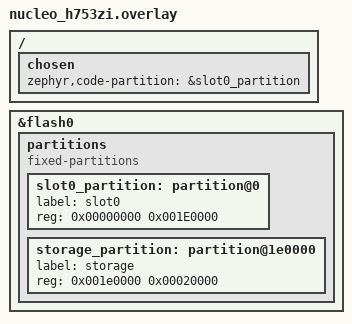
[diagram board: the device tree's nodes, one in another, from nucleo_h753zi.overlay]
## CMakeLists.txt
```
# SPDX-License-Identifier: Apache-2.0

cmake_minimum_required(VERSION 3.20.0)

find_package(Zephyr REQUIRED HINTS $ENV{ZEPHYR_BASE})
find_package(Python REQUIRED COMPONENTS Interpreter)

project(http_server)

if(CONFIG_NET_SOCKETS_SOCKOPT_TLS AND
   CONFIG_MBEDTLS_KEY_EXCHANGE_PSK_ENABLED AND
   (CONFIG_NET_SAMPLE_PSK_HEADER_FILE STREQUAL "dummy_psk.h"))
  add_custom_target(development_psk
    COMMAND ${CMAKE_COMMAND} -E echo "----------------------------------------------------------"
    COMMAND ${CMAKE_COMMAND} -E echo "--- WARNING: Using dummy PSK! Only suitable for        ---"
    COMMAND ${CMAKE_COMMAND} -E echo "--- development. Set NET_SAMPLE_PSK_HEADER_FILE to use ---"
    COMMAND ${CMAKE_COMMAND} -E echo "--- own pre-shared key.                                ---"
    COMMAND ${CMAKE_COMMAND} -E echo "----------------------------------------------------------"
  )
  add_dependencies(app development_psk)
endif()

set(CERTS_DIR ${CMAKE_CURRENT_SOURCE_DIR}/src/certs)

add_custom_target(sample_ca_cert
  WORKING_DIRECTORY ${CERTS_DIR}
  COMMAND sh gen_ca_cert.sh
  COMMENT "Generating sample CA certificate"
)

add_custom_target(sample_server_cert
  WORKING_DIRECTORY ${CERTS_DIR}
  COMMAND sh gen_server_cert.sh
  COMMENT "Generating sample server certificate"
)

option(INCLUDE_HTML_CONTENT "Include the HTML content" ON)

target_sources(app PRIVATE src/main.c
        src/InductionConfig.c
        src/DHCPClient.c
        src/HTTPWebsocket.c
        src/Flash.c
        #src/vlan.c
        #src/HTTPServer.c
)

set(gen_dir ${ZEPHYR_BINARY_DIR}/include/generated/)

target_sources_ifdef(CONFIG_NET_SAMPLE_WEBSOCKET_SERVICE app PRIVATE src/ws.c)
target_sources_ifdef(CONFIG_USB_DEVICE_STACK app PRIVATE src/usb.c)

target_link_libraries(app PRIVATE zephyr_interface zephyr)

zephyr_linker_sources(SECTIONS sections-rom.ld)
zephyr_linker_section_ifdef(CONFIG_NET_SAMPLE_HTTPS_SERVICE NAME
				http_resource_desc_test_https_service
				KVMA RAM_REGION GROUP RODATA_REGION
				SUBALIGN ${CONFIG_LINKER_ITERABLE_SUBALIGN})
zephyr_linker_section_ifdef(CONFIG_NET_SAMPLE_HTTP_SERVICE NAME
				http_resource_desc_test_http_service
				KVMA RAM_REGION GROUP RODATA_REGION
				SUBALIGN ${CONFIG_LINKER_ITERABLE_SUBALIGN})

foreach(web_resource
  index.html
  main.js
    )
  generate_inc_file_for_target(
    app
    src/static_web_resources/${web_resource}
    ${gen_dir}/${web_resource}.gz.inc
    --gzip
  )
endforeach()

foreach(inc_file
	server_cert.der
	server_privkey.der
    )
  generate_inc_file_for_target(
    app
    src/certs/${inc_file}
    ${gen_dir}/${inc_file}.inc
    )
endforeach()
```

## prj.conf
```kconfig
# General config
CONFIG_MAIN_STACK_SIZE=3072
CONFIG_SYSTEM_WORKQUEUE_STACK_SIZE=2048
CONFIG_SHELL=y
CONFIG_LOG=y
CONFIG_ENTROPY_GENERATOR=y
CONFIG_TEST_RANDOM_GENERATOR=y
CONFIG_INIT_STACKS=y
CONFIG_ZVFS_OPEN_MAX=32
CONFIG_POSIX_API=y
CONFIG_FDTABLE=y
CONFIG_ZVFS_POLL_MAX=32

# Eventfd
CONFIG_EVENTFD=y

# Networking config
CONFIG_NETWORKING=y
CONFIG_NET_IPV4=y
CONFIG_NET_IPV6=y
CONFIG_NET_TCP=y
CONFIG_NET_SOCKETS=y
CONFIG_NET_CONNECTION_MANAGER=y
CONFIG_NET_SHELL=y
CONFIG_NET_STATISTICS=y
CONFIG_NET_STATISTICS_USER_API=y
CONFIG_NET_LOG=y

# DHCP client support
CONFIG_NET_DHCPV4=y
CONFIG_NET_MGMT=y
CONFIG_NET_MGMT_EVENT=y
CONFIG_NET_MGMT_EVENT_INFO=y
CONFIG_NET_UDP=y
CONFIG_NET_DHCPV4_OPTION_CALLBACKS=y


# JSON
CONFIG_JSON_LIBRARY=y

# HTTP parser
CONFIG_HTTP_PARSER_URL=y
CONFIG_HTTP_PARSER=y
CONFIG_HTTP_SERVER=y
CONFIG_HTTP_SERVER_WEBSOCKET=y

# Network buffers
CONFIG_NET_PKT_RX_COUNT=16
CONFIG_NET_PKT_TX_COUNT=16
CONFIG_NET_BUF_RX_COUNT=128
CONFIG_NET_BUF_TX_COUNT=128
CONFIG_NET_CONTEXT_NET_PKT_POOL=y

# IP address options
CONFIG_NET_IF_UNICAST_IPV6_ADDR_COUNT=3
CONFIG_NET_IF_MCAST_IPV6_ADDR_COUNT=4
CONFIG_NET_MAX_CONTEXTS=32
CONFIG_NET_MAX_CONN=32

# Network address config
CONFIG_NET_CONFIG_SETTINGS=y
CONFIG_NET_CONFIG_NEED_IPV4=y
CONFIG_NET_CONFIG_NEED_IPV6=y
#CONFIG_NET_CONFIG_MY_IPV4_ADDR="192.0.2.1"
#CONFIG_NET_CONFIG_PEER_IPV4_ADDR="192.0.2.2"
#CONFIG_NET_CONFIG_MY_IPV4_GW="192.0.2.2"
#CONFIG_NET_CONFIG_MY_IPV6_ADDR="2001:db8::1"
#CONFIG_NET_CONFIG_PEER_IPV6_ADDR="2001:db8::2"

# Networking tweaks
# Required to handle large number of consecutive connections,
# e.g. when testing with ApacheBench.
CONFIG_NET_TCP_TIME_WAIT_DELAY=0

# Device drivers
CONFIG_GPIO=y
CONFIG_LED=y

# Network debug config
CONFIG_NET_SOCKETS_LOG_LEVEL_DBG=n
CONFIG_NET_HTTP_LOG_LEVEL_DBG=n
CONFIG_NET_IPV6_LOG_LEVEL_DBG=n
CONFIG_NET_IPV6_ND_LOG_LEVEL_DBG=n

#mDNS Setup
CONFIG_MDNS_RESPONDER=y
CONFIG_MDNS_RESOLVER=y        # if you want resolving on the device too
CONFIG_NET_HOSTNAME_ENABLE=y
CONFIG_NET_HOSTNAME="zephyr"

# POSIX / eventfd support
CONFIG_EVENTFD=y
CONFIG_ZVFS_EVENTFD_MAX=4
CONFIG_ZVFS_OPEN_MAX=32
CONFIG_HEAP_MEM_POOL_SIZE=16384

CONFIG_NET_SAMPLE_WEBSOCKET_SERVICE=y

# Flash Config
CONFIG_SETTINGS=y
CONFIG_SETTINGS_NVS=y
CONFIG_NVS=y
CONFIG_NVS_LOG_LEVEL_INF=y  # optional, for debugging
```

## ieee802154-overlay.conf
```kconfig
CONFIG_NET_L2_IEEE802154=y
CONFIG_NET_L2_IEEE802154_SHELL=y
CONFIG_NET_L2_IEEE802154_LOG_LEVEL_INF=y

# 2.4G by default, SubG bands require additional driver support,
# see *-enable-subg.overlay
# Uncomment for 868 MHz
#CONFIG_NET_CONFIG_IEEE802154_CHANNEL=0
# Uncomment for 906 MHz:
#CONFIG_NET_CONFIG_IEEE802154_CHANNEL=1

CONFIG_NET_MGMT_EVENT_STACK_SIZE=2048
CONFIG_NET_L2_IEEE802154_FRAGMENT_REASS_CACHE_SIZE=3

#Debugging
CONFIG_NET_L2_IEEE802154_LOG_LEVEL_DBG=n
CONFIG_NET_SAMPLE_HTTP_SERVER_SERVICE_PORT=100
```

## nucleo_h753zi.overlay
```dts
/ {
	/* Make sure code-partition still points to your app partition */
	chosen {
		zephyr,code-partition = &slot0_partition;
	};
};

/* Internal flash controller */
&flash0 {
	/* Add or extend partitions node */
	partitions {
		compatible = "fixed-partitions";
		#address-cells = <1>;
		#size-cells = <1>;

		/* This is usually already there; keep whatever your board uses */
		slot0_partition: partition@0 {
			label = "slot0";
			reg = <0x00000000 0x001E0000>; /* example: 1.875 MB for app */
		};

		/* New NVS / settings area at the end of flash */
		storage_partition: partition@1e0000 {
			label = "storage";
			reg = <0x001e0000 0x00020000>; /* 128 KB (one sector) */
		};
	};
};
```

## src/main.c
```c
/*
 * Copyright (c) 2023, Emna Rekik
 * Copyright (c) 2024, Nordic Semiconductor
 *
 * SPDX-License-Identifier: Apache-2.0
 */

#include <stdio.h>
#include <zephyr/kernel.h>
#include <zephyr/logging/log.h>

#include "HTTPWebsocket.h"

LOG_MODULE_REGISTER(main, LOG_LEVEL_DBG);

int main(void)
{
    LOG_INF("Starting HTTP WebSocket Server Application");

    // Initialize the HTTP WebSocket server
    httpwebsocket_init();

    // Start the HTTP server
    int ret = httpwebsocket_start();
    if (ret < 0) {
        LOG_ERR("Failed to start HTTP WebSocket server: %d", ret);
        return ret;
    }

    LOG_INF("HTTP WebSocket Server started successfully");

    return 0;
}
```

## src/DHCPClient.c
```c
/* Networking DHCPv4 client */

/*
 * Copyright (c) 2017 ARM Ltd.
 * Copyright (c) 2016 Intel Corporation.
 *
 * SPDX-License-Identifier: Apache-2.0
 */

#include <zephyr/logging/log.h>
LOG_MODULE_REGISTER(net_dhcpv4_client_sample, LOG_LEVEL_DBG);

#include <zephyr/kernel.h>
#include <zephyr/linker/sections.h>
#include <errno.h>
#include <stdio.h>
#include <stdint.h>

#include <zephyr/net/net_if.h>
#include <zephyr/net/net_core.h>
#include <zephyr/net/net_context.h>
#include <zephyr/net/net_mgmt.h>
#include <zephyr/net/dhcpv4.h>

#include "DHCPClient.h"

typedef struct {
    tcp_info_t tcpInfo;
    bool isValide;
} tcp_info_dhcp_t;

tcp_info_dhcp_t TCPInfoDHCP = {
    .isValide = false
};

#define DHCP_OPTION_NTP (42)

static uint8_t ntp_server[4];

static struct net_mgmt_event_callback mgmt_cb;

static struct net_dhcpv4_option_callback dhcp_cb;

static void start_dhcpv4_client(struct net_if *iface, void *user_data)
{
    ARG_UNUSED(user_data);
    LOG_INF("Start on %s: index=%d", net_if_get_device(iface)->name,
            net_if_get_by_iface(iface));
    net_dhcpv4_start(iface);
}

static void handler(struct net_mgmt_event_callback *cb,
                    uint32_t mgmt_event,
                    struct net_if *iface) {
    int i = 0;
    printk("DHCPHandler called\n");

    if (mgmt_event != NET_EVENT_IPV4_ADDR_ADD) {
        printk("No IPV4 found\n");
        return;
    }

    for (i = 0; i < NET_IF_MAX_IPV4_ADDR; i++) {
        char buf[NET_IPV4_ADDR_LEN];

        //struct net_if_addr *unicast = (net_if_addr*)&iface->config.ip.ipv4->unicast[i];
        if (iface->config.ip.ipv4->unicast[i].ipv4.addr_type != NET_ADDR_DHCP) {
            printk("Net adress not DHCP\n");
            continue;
        }

        printk("\n    Address[%d]: %s\n", net_if_get_by_iface(iface),
                net_addr_ntop(AF_INET,
                    &iface->config.ip.ipv4->unicast[i].ipv4.address.in_addr,
                    buf, sizeof(buf)));
        printk("    Subnet[%d]: %s\n", net_if_get_by_iface(iface),
                net_addr_ntop(AF_INET,
                    &iface->config.ip.ipv4->unicast[i].netmask,
                    buf, sizeof(buf)));
        printk("    Router[%d]: %s\n", net_if_get_by_iface(iface),
                net_addr_ntop(AF_INET,
                    &iface->config.ip.ipv4->gw,
                    buf, sizeof(buf)));
        printk("Lease time[%d]: %u seconds\n", net_if_get_by_iface(iface),
                iface->config.dhcpv4.lease_time);

        /* Store network information in tcpInfo structure */
        memcpy(TCPInfoDHCP.tcpInfo.tcp_4_info, &iface->config.ip.ipv4->unicast[i].ipv4.address.in_addr.s4_addr, 4);
        memcpy(TCPInfoDHCP.tcpInfo.tcp_4_info_router, &iface->config.ip.ipv4->gw.s4_addr, 4);
        memcpy(TCPInfoDHCP.tcpInfo.tcp_4_info_netmask, &iface->config.ip.ipv4->unicast[i].netmask.s4_addr, 4);
        TCPInfoDHCP.tcpInfo.lease_time = iface->config.dhcpv4.lease_time;
        TCPInfoDHCP.isValide = true;

        printk("Scan finished\n");
        net_dhcpv4_stop(iface);
    }
}


static void option_handler(struct net_dhcpv4_option_callback *cb,
                           size_t length,
                           enum net_dhcpv4_msg_type msg_type,
                           struct net_if *iface) {
    char buf[NET_IPV4_ADDR_LEN];

    LOG_INF("DHCP Option %d: %s", cb->option,
            net_addr_ntop(AF_INET, cb->data, buf, sizeof(buf)));
}

bool DHCP_Client_TCP_infos_get(tcp_info_t *tcp_info) 
{
    if (tcp_info == NULL) {
        return false;
    }

    if (!TCPInfoDHCP.isValide) {
        return false;
    }

    *tcp_info = TCPInfoDHCP.tcpInfo;
    return true;
}


int DHCP_Client_init(void) 
{
    LOG_INF("Run dhcpv4 client");

    net_mgmt_init_event_callback(&mgmt_cb, handler,
                                 NET_EVENT_IPV4_ADDR_ADD);
    net_mgmt_add_event_callback(&mgmt_cb);

    net_dhcpv4_init_option_callback(&dhcp_cb, option_handler,
                                    DHCP_OPTION_NTP, ntp_server,
                                    sizeof(ntp_server));

    net_dhcpv4_add_option_callback(&dhcp_cb);

    net_if_foreach(start_dhcpv4_client, NULL);
    return 0;
}
```

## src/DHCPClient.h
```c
#ifndef DHCP_CLIENT_H_
#define DHCP_CLIENT_H_

#include <zephyr/net/net_if.h>
#include <zephyr/net/net_core.h>
#include <zephyr/net/net_context.h>
#include <zephyr/net/net_mgmt.h>
#include <zephyr/net/dhcpv4.h>

#include <zephyr/kernel.h>
#include <zephyr/linker/sections.h>
#include <errno.h>
#include <stdio.h>
#include <stdint.h>

/* TCP/IP information structure */
typedef struct {
    uint8_t tcp_4_info[4];        /* IPv4 address */
    uint8_t tcp_4_info_router[4]; /* Gateway/router address */
    uint8_t tcp_4_info_netmask[4]; /* Subnet mask */
    uint32_t lease_time;          /* DHCP lease time */
} tcp_info_t;

bool DHCP_Client_TCP_infos_get(tcp_info_t *tcp_info);
//bool Net_Credentials_read(tcp_info_t *tcp_info);
//bool NET_Credentials_write(tcp_info_t *tcp_info);
int DHCP_Client_init(void);

#endif // DHCP_CLIENT_H_
```

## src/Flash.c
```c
#include <zephyr/settings/settings.h>
#include <zephyr/storage/flash_map.h>
#include <zephyr/fs/nvs.h>
#include "Flash.h"

#define DHCP_CONFIG_ID 1

#if !DT_NODE_EXISTS(DT_NODELABEL(storage_partition))
#error "storage_partition node not found in devicetree!"
#endif

static struct nvs_fs nvs;

int Flash_SaveNVS(const DHCP_t *cfg)
{
    return nvs_write(&nvs, DHCP_CONFIG_ID, cfg, sizeof(*cfg));
}

int Flash_LoadNVS(DHCP_t *cfg)
{
    int rc = nvs_read(&nvs, DHCP_CONFIG_ID, cfg, sizeof(*cfg));
    if (rc == sizeof(*cfg)) {
        return 0;
    }
    return -ENOENT;
}

int Flash_Init(void)
{
    int rc;

    /* Use the *node label* from DTS: storage_partition */
    nvs.offset       = FIXED_PARTITION_OFFSET(storage_partition);
    nvs.sector_size  = FIXED_PARTITION_SIZE(storage_partition);
    nvs.sector_count = 1;   // whole partition as one NVS area

    rc = nvs_mount(&nvs);
    if (rc) {
        printk("NVS mount failed: %d\n", rc);
        return rc;
    }

    return 0;
}
```

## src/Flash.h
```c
#ifndef FLASH_H_
#define FLASH_H_

#include "InductionConfig.h"

int Flash_SaveNVS(const DHCP_t *cfg);

int Flash_LoadNVS(DHCP_t *cfg);

int Flash_Init(void);

#endif // FLASH_H_
```

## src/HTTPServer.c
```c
/*
 * Copyright (c) 2025
 *
 * SPDX-License-Identifier: Apache-2.0
 */

#include "HTTPServer.h"
#include <stdio.h>
#include <string.h>
#include <zephyr/kernel.h>
#include <zephyr/net/net_if.h>
#include <zephyr/net/net_mgmt.h>
#include <zephyr/net/dhcpv4.h>
#include <zephyr/net/tls_credentials.h>
#include <zephyr/net/http/server.h>
#include <zephyr/net/http/service.h>
#include <zephyr/net/net_ip.h>
#include <zephyr/net/socket.h>

#include <zephyr/logging/log.h>
LOG_MODULE_REGISTER(http_server_module, LOG_LEVEL_DBG);

/* Include certificates if HTTPS is enabled */
#if defined(CONFIG_NET_SAMPLE_HTTPS_SERVICE)
#include "certificate.h"
#endif

static struct net_mgmt_event_callback mgmt_cb;
static struct k_sem dhcp_sem;
static bool dhcp_configured = false;
static struct http_server_config server_config;

/**
 * @brief Network management event handler
 */
static void net_mgmt_event_handler(struct net_mgmt_event_callback *cb,
				  uint32_t mgmt_event,
				  struct net_if *iface)
{
	switch (mgmt_event) {
	case NET_EVENT_IPV4_DHCP_BOUND:
		LOG_INF("IPv4 DHCP bound");
		dhcp_configured = true;
		k_sem_give(&dhcp_sem);
		break;
	case NET_EVENT_IPV4_ADDR_ADD:
		LOG_INF("IPv4 address added to interface");
		break;
	case NET_EVENT_IPV4_ADDR_DEL:
		LOG_INF("IPv4 address removed from interface");
		dhcp_configured = false;
		break;
	case NET_EVENT_IPV4_DHCP_START:
		LOG_INF("IPv4 DHCP started");
		break;
	case NET_EVENT_IPV4_DHCP_STOP:
		LOG_INF("IPv4 DHCP stopped");
		break;
	default:
		break;
	}
}

/**
 * @brief Configure network interface with static IP
 */
static int configure_static_ip(struct net_if *iface, const struct http_server_config *config)
{
	struct in_addr addr;
	struct in_addr netmask;
	struct in_addr gw;
	int ret;

	if (!config->ipv4_addr) {
		LOG_ERR("Static IP address is required");
		return -EINVAL;
	}

	/* Parse and set IPv4 address */
	ret = inet_pton(AF_INET, config->ipv4_addr, &addr);
	if (ret != 1) {
		LOG_ERR("Invalid IPv4 address: %s", config->ipv4_addr);
		return -EINVAL;
	}

	ret = net_if_ipv4_addr_add(iface, &addr, NET_ADDR_MANUAL, 0);
	if (ret < 0) {
		LOG_ERR("Failed to add IPv4 address: %d", ret);
		return ret;
	}

	/* Set netmask if provided */
	if (config->ipv4_netmask) {
		ret = inet_pton(AF_INET, config->ipv4_netmask, &netmask);
		if (ret == 1) {
			net_if_ipv4_set_netmask(iface, &netmask);
		} else {
			LOG_WRN("Invalid netmask, using default");
		}
	}

	/* Set gateway if provided */
	if (config->ipv4_gw) {
		ret = inet_pton(AF_INET, config->ipv4_gw, &gw);
		if (ret == 1) {
			net_if_ipv4_set_gw(iface, &gw);
		} else {
			LOG_WRN("Invalid gateway address");
		}
	}

	LOG_INF("Static IP configuration applied: %s", config->ipv4_addr);
	return 0;
}

/**
 * @brief Configure network interface with DHCP
 */
static int configure_dhcp(struct net_if *iface)
{
	int ret;

	/* Initialize DHCP semaphore */
	k_sem_init(&dhcp_sem, 0, 1);

	/* Register network management event callback */
	net_mgmt_init_event_callback(&mgmt_cb, net_mgmt_event_handler,
				     NET_EVENT_IPV4_DHCP_BOUND |
				     NET_EVENT_IPV4_ADDR_ADD |
				     NET_EVENT_IPV4_ADDR_DEL |
				     NET_EVENT_IPV4_DHCP_START |
				     NET_EVENT_IPV4_DHCP_STOP);

	net_mgmt_add_event_callback(&mgmt_cb);

	/* Start DHCP client */
	ret = net_dhcpv4_start(iface);
	if (ret < 0) {
		LOG_ERR("Failed to start DHCPv4 client: %d", ret);
		net_mgmt_del_event_callback(&mgmt_cb);
		return ret;
	}

	LOG_INF("DHCP client started, waiting for IP address...");

	/* Wait for DHCP to complete (timeout: 30 seconds) */
	ret = k_sem_take(&dhcp_sem, K_SECONDS(30));
	if (ret < 0) {
		LOG_ERR("DHCP timeout");
		net_dhcpv4_stop(iface);
		net_mgmt_del_event_callback(&mgmt_cb);
		return -ETIMEDOUT;
	}

	if (!dhcp_configured) {
		LOG_ERR("DHCP configuration failed");
		net_mgmt_del_event_callback(&mgmt_cb);
		return -ENONET;
	}

	LOG_INF("DHCP configuration completed successfully");
	return 0;
}

int http_server_setup_tls(void)
{
#if defined(CONFIG_NET_SAMPLE_HTTPS_SERVICE)
#if defined(CONFIG_NET_SOCKETS_SOCKOPT_TLS)
	int err;

	err = tls_credential_add(HTTP_SERVER_CERTIFICATE_TAG,
				 TLS_CREDENTIAL_SERVER_CERTIFICATE,
				 server_certificate,
				 sizeof(server_certificate));
	if (err < 0) {
		LOG_ERR("Failed to register public certificate: %d", err);
		return err;
	}

	err = tls_credential_add(HTTP_SERVER_CERTIFICATE_TAG,
				 TLS_CREDENTIAL_PRIVATE_KEY,
				 private_key, sizeof(private_key));
	if (err < 0) {
		LOG_ERR("Failed to register private key: %d", err);
		return err;
	}

#if defined(CONFIG_MBEDTLS_KEY_EXCHANGE_PSK_ENABLED)
	err = tls_credential_add(PSK_TAG,
				 TLS_CREDENTIAL_PSK,
				 psk,
				 sizeof(psk));
	if (err < 0) {
		LOG_ERR("Failed to register PSK: %d", err);
		return err;
	}

	err = tls_credential_add(PSK_TAG,
				 TLS_CREDENTIAL_PSK_ID,
				 psk_id,
				 sizeof(psk_id) - 1);
	if (err < 0) {
		LOG_ERR("Failed to register PSK ID: %d", err);
		return err;
	}
#endif /* defined(CONFIG_MBEDTLS_KEY_EXCHANGE_PSK_ENABLED) */

	LOG_INF("TLS credentials configured successfully");
#endif /* defined(CONFIG_NET_SOCKETS_SOCKOPT_TLS) */
#else
	LOG_INF("HTTPS service not enabled, skipping TLS setup");
#endif /* defined(CONFIG_NET_SAMPLE_HTTPS_SERVICE) */
	return 0;
}

int http_server_init_and_start(const struct http_server_config *config)
{
	struct net_if *iface;
	int ret;

	if (!config) {
		LOG_ERR("Invalid configuration");
		return -EINVAL;
	}

	/* Store configuration */
	memcpy(&server_config, config, sizeof(struct http_server_config));

	/* Get default network interface */
	iface = net_if_get_default();
	if (!iface) {
		LOG_ERR("No network interface available");
		return -ENODEV;
	}

	LOG_INF("Configuring network interface...");

	/* Configure IP address */
	if (config->use_dhcp) {
		ret = configure_dhcp(iface);
		if (ret < 0) {
			LOG_ERR("DHCP configuration failed: %d", ret);
			return ret;
		}
	} else {
		ret = configure_static_ip(iface, config);
		if (ret < 0) {
			LOG_ERR("Static IP configuration failed: %d", ret);
			return ret;
		}
	}

	/* Setup TLS if HTTPS is enabled */
	if (config->enable_https) {
		ret = http_server_setup_tls();
		if (ret < 0) {
			LOG_ERR("TLS setup failed: %d", ret);
			return ret;
		}
	}

	/* Start HTTP server */
	LOG_INF("Starting HTTP server...");
	ret = http_server_start();
	if (ret < 0) {
		LOG_ERR("Failed to start HTTP server: %d", ret);
		return ret;
	}

	LOG_INF("HTTP server started successfully");

	/* Print IP information */
	char ip_str[16];
	ret = http_server_get_ip_info(ip_str, sizeof(ip_str));
	if (ret == 0) {
		LOG_INF("HTTP server accessible at:");
		if (config->enable_http) {
			LOG_INF("  HTTP:  http://%s:%d", ip_str, config->http_port);
		}
		if (config->enable_https) {
			LOG_INF("  HTTPS: https://%s:%d", ip_str, config->https_port);
		}
	}

	return 0;
}

int http_server_stop_service(void)
{
	int ret;

	LOG_INF("Stopping HTTP server...");

	ret = http_server_stop();
	if (ret < 0) {
		LOG_ERR("Failed to stop HTTP server: %d", ret);
		return ret;
	}

	/* Stop DHCP if it was used */
	if (server_config.use_dhcp && dhcp_configured) {
		struct net_if *iface = net_if_get_default();
		if (iface) {
			net_dhcpv4_stop(iface);
			net_mgmt_del_event_callback(&mgmt_cb);
			dhcp_configured = false;
		}
	}

	LOG_INF("HTTP server stopped successfully");
	return 0;
}

int http_server_get_ip_info(char *ipv4_addr, size_t ipv4_addr_len)
{
	struct net_if *iface;
	struct net_if_ipv4 *ipv4;

	if (!ipv4_addr || ipv4_addr_len < 16) {
		return -EINVAL;
	}

	iface = net_if_get_default();
	if (!iface) {
		return -ENODEV;
	}

	ipv4 = iface->config.ip.ipv4;
	if (!ipv4 || ipv4->unicast[0].addr_type == NET_ADDR_OVERRIDABLE) {
		return -ENONET;
	}

	net_addr_ntop(AF_INET, &ipv4->unicast[0].address.in_addr, 
		      ipv4_addr, ipv4_addr_len);

	return 0;
}
```

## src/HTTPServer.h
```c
/*
 * Copyright (c) 2025
 *
 * SPDX-License-Identifier: Apache-2.0
 */

#ifndef __HTTP_SERVER_H__
#define __HTTP_SERVER_H__

#include <zephyr/kernel.h>
#include <zephyr/net/net_ip.h>

#ifdef __cplusplus
extern "C" {
#endif

/**
 * @brief HTTP Server Configuration Structure
 */
struct http_server_config {
	/** IPv4 address to bind to (optional, can be NULL for DHCP) */
	const char *ipv4_addr;
	/** IPv4 gateway address (optional) */
	const char *ipv4_gw;
	/** IPv4 subnet mask (optional) */
	const char *ipv4_netmask;
	/** Use DHCP for IPv4 configuration */
	bool use_dhcp;
	/** HTTP port */
	uint16_t http_port;
	/** HTTPS port */
	uint16_t https_port;
	/** Enable HTTP service */
	bool enable_http;
	/** Enable HTTPS service */
	bool enable_https;
};

/**
 * @brief Initialize and start HTTP server with custom IP configuration
 *
 * This function configures the network interface with either static IP
 * or DHCP, sets up TLS credentials if needed, and starts the HTTP server.
 *
 * @param config Pointer to HTTP server configuration structure
 * @return 0 on success, negative error code on failure
 */
int http_server_init_and_start(const struct http_server_config *config);

/**
 * @brief Stop the HTTP server
 *
 * @return 0 on success, negative error code on failure
 */
int http_server_stop_service(void);

/**
 * @brief Get current network interface information
 *
 * @param ipv4_addr Buffer to store IPv4 address (minimum 16 bytes)
 * @param ipv4_addr_len Length of ipv4_addr buffer
 * @return 0 on success, negative error code on failure
 */
int http_server_get_ip_info(char *ipv4_addr, size_t ipv4_addr_len);

/**
 * @brief Setup TLS credentials for HTTPS
 *
 * @return 0 on success, negative error code on failure
 */
int http_server_setup_tls(void);

#ifdef __cplusplus
}
#endif

#endif /* __HTTP_SERVER_H__ */
```

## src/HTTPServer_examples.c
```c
/*
 * HTTPServer Usage Examples
 * 
 * This file demonstrates how to use the HTTPServer module with different
 * network configurations.
 */

#include "HTTPServer.h"
#include <zephyr/logging/log.h>

/* Example 1: Using DHCP (recommended for most cases) */
void example_dhcp_server(void)
{
	struct http_server_config config = {
		.ipv4_addr = NULL,        /* Not used with DHCP */
		.ipv4_gw = NULL,         /* Not used with DHCP */
		.ipv4_netmask = NULL,    /* Not used with DHCP */
		.use_dhcp = true,        /* Enable DHCP */
		.http_port = 80,         /* HTTP port */
		.https_port = 443,       /* HTTPS port */
		.enable_http = true,     /* Enable HTTP service */
		.enable_https = false,   /* Disable HTTPS service */
	};

	int ret = http_server_init_and_start(&config);
	if (ret < 0) {
		printk("Failed to start DHCP HTTP server: %d\n", ret);
	} else {
		printk("DHCP HTTP server started successfully\n");
	}
}

/* Example 2: Using static IP address */
void example_static_ip_server(void)
{
	struct http_server_config config = {
		.ipv4_addr = "192.168.1.100",    /* Static IP address */
		.ipv4_gw = "192.168.1.1",       /* Gateway address */
		.ipv4_netmask = "255.255.255.0", /* Subnet mask */
		.use_dhcp = false,               /* Disable DHCP */
		.http_port = 8080,               /* Custom HTTP port */
		.https_port = 8443,              /* Custom HTTPS port */
		.enable_http = true,             /* Enable HTTP service */
		.enable_https = true,            /* Enable HTTPS service */
	};

	int ret = http_server_init_and_start(&config);
	if (ret < 0) {
		printk("Failed to start static IP HTTP server: %d\n", ret);
	} else {
		printk("Static IP HTTP server started successfully\n");
		
		/* Get and print current IP information */
		char ip_str[16];
		ret = http_server_get_ip_info(ip_str, sizeof(ip_str));
		if (ret == 0) {
			printk("Server IP: %s\n", ip_str);
			printk("HTTP URL:  http://%s:%d\n", ip_str, config.http_port);
			printk("HTTPS URL: https://%s:%d\n", ip_str, config.https_port);
		}
	}
}

/* Example 3: HTTPS-only server with DHCP */
void example_https_only_server(void)
{
	struct http_server_config config = {
		.ipv4_addr = NULL,
		.ipv4_gw = NULL,
		.ipv4_netmask = NULL,
		.use_dhcp = true,         /* Use DHCP */
		.http_port = 80,          /* HTTP port (not used) */
		.https_port = 443,        /* HTTPS port */
		.enable_http = false,     /* Disable HTTP service */
		.enable_https = true,     /* Enable HTTPS service only */
	};

	int ret = http_server_init_and_start(&config);
	if (ret < 0) {
		printk("Failed to start HTTPS-only server: %d\n", ret);
	} else {
		printk("HTTPS-only server started successfully\n");
	}
}

/* Example 4: How to stop the server */
void example_stop_server(void)
{
	int ret = http_server_stop_service();
	if (ret < 0) {
		printk("Failed to stop HTTP server: %d\n", ret);
	} else {
		printk("HTTP server stopped successfully\n");
	}
}
```

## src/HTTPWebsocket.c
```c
/*
 * Copyright (c) 2023, Emna Rekik
 * Copyright (c) 2024, Nordic Semiconductor
 *
 * SPDX-License-Identifier: Apache-2.0
 */

#include "HTTPWebsocket.h"
#include "DHCPClient.h"
#include "ws.h"

#include <stdio.h>
#include <zephyr/net/net_ip.h>
#include <zephyr/net/socket.h>
#include <zephyr/net/dhcpv4.h>
#include <zephyr/logging/log.h>

LOG_MODULE_REGISTER(httpwebsocket, LOG_LEVEL_DBG);

// Static web resources
static uint8_t index_html_gz[] = {
#include "index.html.gz.inc"
};

static uint8_t main_js_gz[] = {
#include "main.js.gz.inc"
};

static uint8_t WebsocketBuffer[1024];

// HTTP resource definitions
static struct http_resource_detail_static HTMLResource = {
    .common = {
        .type = HTTP_RESOURCE_TYPE_STATIC,
        .bitmask_of_supported_http_methods = BIT(HTTP_GET),
        .content_encoding = "gzip",
        .content_type = "text/html",
    },
    .static_data = index_html_gz,
    .static_data_len = sizeof(index_html_gz),
};

static struct http_resource_detail_static MainJSResource = {
    .common = {
        .type = HTTP_RESOURCE_TYPE_STATIC,
        .bitmask_of_supported_http_methods = BIT(HTTP_GET),
        .content_encoding = "gzip",
        .content_type = "text/javascript",
    },
    .static_data = main_js_gz,
    .static_data_len = sizeof(main_js_gz),
};

struct http_resource_detail_websocket WSEcho = {
    .common = {
        .type = HTTP_RESOURCE_TYPE_WEBSOCKET,
        // We need HTTP/1.1 Get method for upgrading
        .bitmask_of_supported_http_methods = BIT(HTTP_GET),
    },
    .cb = ws_echo_setup,
    .data_buffer = WebsocketBuffer,
    .data_buffer_len = sizeof(WebsocketBuffer),
    .user_data = NULL, // Fill this for any user specific data
};

// HTTP service configuration
static uint16_t test_http_service_port = CONFIG_NET_SAMPLE_HTTP_SERVER_SERVICE_PORT;

HTTP_SERVICE_DEFINE(test_http_service, NULL, &test_http_service_port, 1,
                    10, NULL, NULL);

HTTP_RESOURCE_DEFINE(index_html_gz_resource, test_http_service, "/",
                     &HTMLResource);

HTTP_RESOURCE_DEFINE(main_js_gz_resource, test_http_service, "/main.js",
                     &MainJSResource);

HTTP_RESOURCE_DEFINE(WSEchoResource, test_http_service, "/ws_echo", &WSEcho);

// Network interface management
static struct net_if *Interface = NULL;

void httpwebsocket_interface_init(void)
{
    Interface = net_if_get_default();
}

void httpwebsocket_start_dhcp(void)
{
    if (Interface) {
        net_dhcpv4_start(Interface);
    }
}

void httpwebsocket_set_static_ip(void)
{
    printk("Use Static IP\n");

    if (!Interface) {
        LOG_ERR("Network interface not initialized");
        return;
    }

    /* Stop DHCP and drop lease */
    net_dhcpv4_stop(Interface);

    /* Optional: configure static IPv4 */
    struct in_addr addr, netmask, gw;

    inet_pton(AF_INET, "192.168.1.100", &addr);
    inet_pton(AF_INET, "255.255.255.0", &netmask);
    inet_pton(AF_INET, "192.168.1.1", &gw);

    net_if_ipv4_addr_add(Interface, &addr, NET_ADDR_MANUAL, 0);
    net_if_ipv4_set_netmask_by_addr(Interface, &addr, &netmask);
    net_if_ipv4_set_gw(Interface, &gw);
}

void httpwebsocket_static_ip_mode(void)
{
    httpwebsocket_interface_init();
    http_server_stop();
    httpwebsocket_set_static_ip();
}

void httpwebsocket_init(void)
{
    httpwebsocket_interface_init();
    LOG_INF("HTTP WebSocket server initialized");
}

int httpwebsocket_start(void)
{
    int ret = http_server_start();
    if (ret < 0) {
        LOG_ERR("Failed to start HTTP server: %d", ret);
        return ret;
    }

    LOG_INF("HTTP WebSocket server started on port %d", test_http_service_port);
    return 0;
}

int httpwebsocket_stop(void)
{
    int ret = http_server_stop();
    if (ret < 0) {
        LOG_ERR("Failed to stop HTTP server: %d", ret);
        return ret;
    }

    LOG_INF("HTTP WebSocket server stopped");
    return 0;
}
```

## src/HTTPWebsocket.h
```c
/*
 * Copyright (c) 2023, Emna Rekik
 * Copyright (c) 2024, Nordic Semiconductor
 *
 * SPDX-License-Identifier: Apache-2.0
 */

#ifndef HTTPWEBSOCKET_H
#define HTTPWEBSOCKET_H

#include <zephyr/kernel.h>
#include <zephyr/net/http/server.h>
#include <zephyr/net/http/service.h>
#include <zephyr/net/net_if.h>

/**
 * @brief Initialize the HTTP/WebSocket server
 *
 * Sets up all HTTP resources, services, and starts the server.
 */
void httpwebsocket_init(void);

/**
 * @brief Start the HTTP server
 *
 * @return 0 on success, negative error code on failure
 */
int httpwebsocket_start(void);

/**
 * @brief Stop the HTTP server
 *
 * @return 0 on success, negative error code on failure
 */
int httpwebsocket_stop(void);

/**
 * @brief Initialize network interface
 */
void httpwebsocket_interface_init(void);

/**
 * @brief Start DHCP client
 */
void httpwebsocket_start_dhcp(void);

/**
 * @brief Configure static IP and stop DHCP
 */
void httpwebsocket_set_static_ip(void);

/**
 * @brief Switch to static IP configuration
 */
void httpwebsocket_static_ip_mode(void);

#endif /* HTTPWEBSOCKET_H */
```

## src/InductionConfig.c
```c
#include <zephyr/kernel.h>
#include <zephyr/data/json.h>
#include "InductionConfig.h"



bool InductionConfig_json_parser(char *data, uint32_t size)
{

  DHCP_t dhcp;
  uint8_t json_msg[] = "{\"DHCP\":\"on\",\"IP4Address\":\"192.0.2.1\",\"NetMask\":\"255.255.255.0\",\"isEnabled_CAN_1_0\":1,\"isEnabled_CAN_1_1\":0,\"isEnabled_CAN_1_2\":0,\"isEnabled_CAN_1_3\":0,\"isEnabled_CAN_2_0\":0,\"isEnabled_CAN_2_1\":0,\"isEnabled_CAN_2_2\":0,\"isEnabled_CAN_2_3\":0}";

  static const struct json_obj_descr DHCPDescriptor[] = {
      JSON_OBJ_DESCR_PRIM(DHCP_t, DHCP, JSON_TOK_STRING),
      JSON_OBJ_DESCR_PRIM(DHCP_t, IP4Address, JSON_TOK_STRING),
      JSON_OBJ_DESCR_PRIM(DHCP_t, NetMask, JSON_TOK_STRING),
      JSON_OBJ_DESCR_PRIM(DHCP_t, isEnabled_CAN_1_0, JSON_TOK_NUMBER),
      JSON_OBJ_DESCR_PRIM(DHCP_t, isEnabled_CAN_1_1, JSON_TOK_NUMBER),
      JSON_OBJ_DESCR_PRIM(DHCP_t, isEnabled_CAN_1_2, JSON_TOK_NUMBER),
      JSON_OBJ_DESCR_PRIM(DHCP_t, isEnabled_CAN_1_3, JSON_TOK_NUMBER),
      JSON_OBJ_DESCR_PRIM(DHCP_t, isEnabled_CAN_2_0, JSON_TOK_NUMBER),
      JSON_OBJ_DESCR_PRIM(DHCP_t, isEnabled_CAN_2_1, JSON_TOK_NUMBER),
      JSON_OBJ_DESCR_PRIM(DHCP_t, isEnabled_CAN_2_2, JSON_TOK_NUMBER),
      JSON_OBJ_DESCR_PRIM(DHCP_t, isEnabled_CAN_2_3, JSON_TOK_NUMBER),
  };

  int64_t ret = json_obj_parse(data, size, DHCPDescriptor, ARRAY_SIZE(DHCPDescriptor), &dhcp);
  if (ret < 0)
  {
    printk("JSON Parse Error: %d\n", ret);
    return false;
  }
  else
  {
    printk("json_obj_parse return code: %d\n", ret);
    printk("DHCP:                       %s\n", dhcp.DHCP);
    printk("IP4Address                  %s\n", dhcp.IP4Address);
    printk("NetMask:                    %s\n", dhcp.NetMask);
    printk("isEnabled_CAN_1_0           %i\n", dhcp.isEnabled_CAN_1_0);
    printk("isEnabled_CAN_2_3           %i\n", dhcp.isEnabled_CAN_2_3);
  }

  printk("Exit\n");
  return true;
}
```

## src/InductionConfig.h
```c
#ifndef INDUCTION_CONFIG_H_
#define INDUCTION_CONFIG_H_

#include <stdbool.h>

typedef struct
{
    const char *DHCP;
    const char *IP4Address;
    const char *NetMask;
    const int *isEnabled_CAN_1_0;
    const int *isEnabled_CAN_1_1;
    const int *isEnabled_CAN_1_2;
    const int *isEnabled_CAN_1_3;
    const int *isEnabled_CAN_2_0;
    const int *isEnabled_CAN_2_1;
    const int *isEnabled_CAN_2_2;
    const int *isEnabled_CAN_2_3;
} DHCP_t;

bool InductionConfig_json_parser(char *data, uint32_t size);


#endif // INDUCITON_CONFIG_H_
```

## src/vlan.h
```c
#ifndef VLAN_H_
#define VLAN_H_


int init_vlan(void);


#endif // VLAN_H_
```
